# TC37XPD register map
Vendor: Infineon; Series: ATVMC; File version: 100
CPU: other r0p0, little endian, MPU, FPU, vendor SysTick, 4 interrupt priority bits
Registers are 32-bit, read-write, reset 0x0 unless marked. A register's access mark holds for its fields unless they carry their own. Offsets are from the block's base; [hi:lo] are bit positions; lines under a group give offsets from that group; {n}, {i} and the like mark numbered series; 'fields as' and 'values as' point back to an identical list.

## GTM (part 1 of 13)
Base 0xF0100000
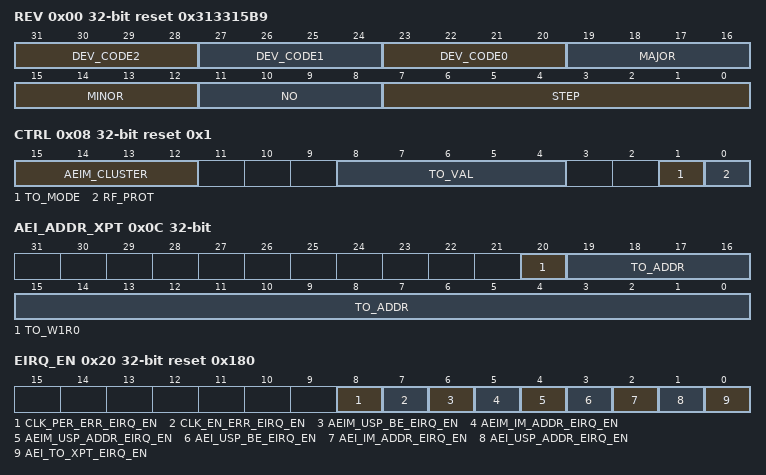
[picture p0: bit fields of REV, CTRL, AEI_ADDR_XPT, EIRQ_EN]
0x00 REV ro reset 0x313315B9 — GTM Version Control Register resetvalue={Application Reset:0x313315B9}
  [31:28] DEV_CODE2 — Device encoding digit 2. Device encoding digit 2.
  [27:24] DEV_CODE1 — Device encoding digit 1. Device encoding digit 1.
  [23:20] DEV_CODE0 — Device encoding digit 0. Device encoding digit 0.
  [19:16] MAJOR — Major version number. Define major version number of GTM specification.
  [15:12] MINOR — Minor version number. Define minor version number of GTM specification.
  [11:8] NO — Delivery number. Define delivery number of GTM specification.
  [7:0] STEP — Release step. GTM Release step
0x04 RST — GTM Global Reset Register resetvalue={Application Reset:0x0}
  [27] BRIDGE_MODE_WRDIS — GTM BRIDGE MODE write disable. This bit is write protected by bit RF PROT
0x08 CTRL access per field reset 0x1 — GTM Global Control Register resetvalue={Application Reset:0x1}
  [15:12] AEIM_CLUSTER ro — AEIM cluster number. These bits show the number of the AEI master port cluster which throws the interrupts AEIM USP ADDR AEIM IM ADDR and AEIM USP BE depending on the AEI master port access status.Note If one of the corresponding irq notify bits 6 4 is set this bit field will be frozen until the interrupt notify bits 6 4 are cleared.
  [8:4] TO_VAL rw — AEI timeout value. These bits define the number of cycles after which a timeout event occurs. When TO VAL equals zero 0 the AEI timeout functionality is disabled.
  [1] TO_MODE rw — AEI timeout mode
  [0] RF_PROT rw — RST and FORCINT protection
0x0C AEI_ADDR_XPT ro — GTM AEI Timeout Exception Address Register resetvalue={Application Reset:0x0}
  [20] TO_W1R0 — AEI timeout Read Write flag. This bit defines the AEI Read Write flag for which the AEI timeout event occurred.
  [19:0] TO_ADDR — AEI timeout address. This bit field defines the AEI address for which the AEI timeout event occurred.
0x10 IRQ group
  0x00 NOTIFY access per field — GTM Interrupt Notification Register resetvalue={Application Reset:0x0}
    [29] CLK_EN_EXP_STATE1 ro — Expected clock enable state. This bit field defines the GTM expected clk enable state for internal clock aei sys clk 2 at occurrence of the CLK EN ERR event. Function only available with INT CLK EN GEN 0b0 Read as zero in case of INT CLK EN GEN 0b1.
    [28] CLK_EN_EXP_STATE0 ro — Expected clock enable state. This bit field defines the GTM expected clk enable state for internal clock aei sys clk at occurrence of the CLK EN ERR event. Function only available with INT CLK EN GEN 0b0 Read as zero in case of INT CLK EN GEN 0b1.
    [25] CLK_EN_ERR_STATE1 ro — Erroneous clock enable state. This bit field defines the GTM external clk enable state for internal clock aei sys clk 2 at occurrence of the CLK EN ERR event. Function only available with INT CLK EN GEN 0b0 Read as zero in case of INT CLK EN GEN 0b1.
    [24] CLK_EN_ERR_STATE0 ro — Erroneous clock enable state. This bit field defines the GTM external clk enable state for internal clock aei sys clkat occurrence of the CLK EN ERR event. Function only available with INT CLK EN GEN 0b0 Read as zero in case of INT CLK EN GEN 0b1.
    [8] CLK_PER_ERR rw — Clock period error interrupt. This bit will be cleared on a CPU write access of value 1 . A read access leaves the bit unchanged. Read as zero in case of INT CLK EN GEN 0b1.
    [7] CLK_EN_ERR rw — Clock enable error interrupt. This bit will be cleared on a CPU write access of value 1 . A read access leaves the bit unchanged. Read as zero in case of INT CLK EN GEN 0b1.
    [6] AEIM_USP_BE rw — AEI master port unsupported byte enable interrupt. This bit will be cleared on a CPU write access of value 1 . A read access leaves the bit unchanged.
    [5] AEIM_IM_ADDR rw — AEI master port illegal Module address interrupt. This bit will be cleared on a CPU write access of value 1 . A read access leaves the bit unchanged.
    [4] AEIM_USP_ADDR rw — AEI master port unsupported address interrupt. This bit will be cleared on a CPU write access of value 1 . A read access leaves the bit unchanged.
    [3] AEI_USP_BE rw — AEI unsupported byte enable interrupt. This bit will be cleared on a CPU write access of value 1 . A read access leaves the bit unchanged.
    [2] AEI_IM_ADDR rw — AEI illegal Module address interrupt. This bit will be cleared on a CPU write access of value 1 . A read access leaves the bit unchanged.
    [1] AEI_USP_ADDR rw — AEI unsupported address interrupt. This bit will be cleared on a CPU write access of value 1 . A read access leaves the bit unchanged.
    [0] AEI_TO_XPT rw — AEI timeout exception occurred. This bit will be cleared on a CPU write access of value 1 . As the bit is rw otherwise no clear. A read access leaves the bit unchanged.
  0x04 EN — GTM Interrupt Enable Register resetvalue={Application Reset:0x0}
    [8] CLK_PER_ERR_IRQ_EN — CLK PER ERR IRQ interrupt enable. Read as zero in case of INT CLK EN GEN 0b1.
    [7] CLK_EN_ERR_IRQ_EN — CLK EN ERR IRQ interrupt enable. Read as zero in case of INT CLK EN GEN 0b1.
    [6] AEIM_USP_BE_IRQ_EN — AEIM USP BE IRQ interrupt enable
    [5] AEIM_IM_ADDR_IRQ_EN — AEIM IM ADDR IRQ interrupt enable
    [4] AEIM_USP_ADDR_IRQ_EN — AEI MUSP ADDR IRQ interrupt enable
    [3] AEI_USP_BE_IRQ_EN — AEI USP BE IRQ interrupt enable
    [2] AEI_IM_ADDR_IRQ_EN — AEI IM ADDR IRQ interrupt enable
    [1] AEI_USP_ADDR_IRQ_EN — AEI USP ADDR IRQ interrupt enable
    [0] AEI_TO_XPT_IRQ_EN — AEI TO XPT IRQ interrupt enable
  0x08 FORCINT — GTM Software Interrupt Generation Register resetvalue={Application Reset:0x0}
    [8] TRG_CLK_PER_ERR — Trigger CLK PER ERR IRQ interrupt by software. This bit is cleared automatically after write. This bit is write protected by bit RF PROT of CTRL Read as zero in case of INT CLK EN GEN 0b1.
    [7] TRG_CLK_EN_ERR — Trigger CLK EN ERR IRQ interrupt by software. This bit is cleared automatically after write. This bit is write protected by bit RF PROT of CTRL Read as zero in case of INT CLK EN GEN 0b1.
    [6] TRG_AEIM_USP_BE — Trigger AEIM USP BE IRQ interrupt by software. This bit is cleared automatically after write. This bit is write protected by bit RF PROT of CTRL
    [5] TRG_AEIM_IM_ADDR — Trigger AEIM IM ADDR IRQ interrupt by software. This bit is cleared automatically after write. This bit is write protected by bit RF PROT of CTRL
    [4] TRG_AEIM_USP_ADDR — Trigger AEIM USP ADDR IRQ interrupt by software. This bit is cleared automatically after write. This bit is write protected by bit RF PROT of CTRL
    [3] TRG_AEI_USP_BE — Trigger AEI USP BE IRQ interrupt by software. This bit is cleared automatically after write. This bit is write protected by bit RF PROT of CTRL
    [2] TRG_AEI_IM_ADDR — Trigger AEI IM ADDR IRQ interrupt by software. This bit is cleared automatically after write. This bit is write protected by bit RF PROT of CTRL
    [1] TRG_AEI_USP_ADDR — Trigger AEI USP ADDR IRQ interrupt by software. This bit is cleared automatically after write. This bit is write protected by bit RF PROT of CTRL
    [0] TRG_AEI_TO_XPT — Trigger AEI TO XPT IRQ interrupt by software. This bit is cleared automatically after write. This bit is write protected by bit RF PROT of CTRL
  0x0C MODE — GTM Top Level Interrupts Mode Selection Register resetvalue={Application Reset:0x0}
    [1:0] IRQ_MODE — Interrupt strategy mode selection for the AEI timeout and address monitoring interrupts. The interrupt modes are described in CROSSREFERENCE .Note This mode selection is only valid for the six interrupts described in section CROSSREFERENCE
0x20 EIRQ_EN reset 0x180 — GTM Error Interrupt Enable Register resetvalue={Application Reset:0x180}
  [8] CLK_PER_ERR_EIRQ_EN — CLK PER ERR EIRQ interrupt enable. Read as zero in case of INT CLK EN GEN 0b1. Read as zero shall be written as zero.
  [7] CLK_EN_ERR_EIRQ_EN — CLK EN ERR EIRQ interrupt enable. Read as zero in case of INT CLK EN GEN 0b1.
  [6] AEIM_USP_BE_EIRQ_EN — AEIM USP BE EIRQ error interrupt enable
  [5] AEIM_IM_ADDR_EIRQ_EN — AEIM IM ADDR EIRQ error interrupt enable
  [4] AEIM_USP_ADDR_EIRQ_EN — AEIM USP ADDR EIRQ error interrupt enable
  [3] AEI_USP_BE_EIRQ_EN — AEI USP BE EIRQ error interrupt enable
  [2] AEI_IM_ADDR_EIRQ_EN — AEI IM ADDR EIRQ error interrupt enable
  [1] AEI_USP_ADDR_EIRQ_EN — AEI USP ADDR EIRQ error interrupt enable
  [0] AEI_TO_XPT_EIRQ_EN — AEI TO XPT EIRQ error interrupt enable
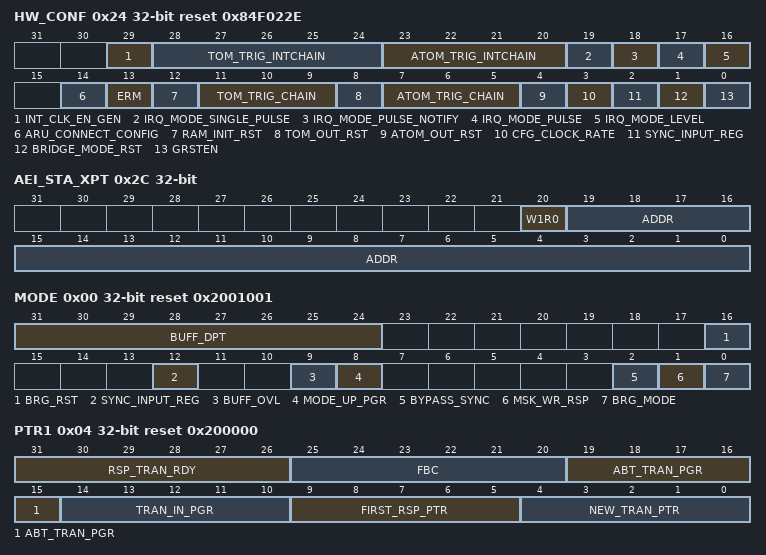
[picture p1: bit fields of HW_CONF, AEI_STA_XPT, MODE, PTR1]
0x24 HW_CONF ro reset 0x84F022E — GTM Hardware Configuration Register resetvalue={Application Reset:0x084F022E}
  [29] INT_CLK_EN_GEN — Internal clock enable generation
  [28:24] TOM_TRIG_INTCHAIN — TOM internal trigger chain length without synchronization register. It defines after which TOM channel count a synchronization register is introduced into trigger chain. Valid values are 1 to 16. 8 means that in channel 8 of the tom instances a synchronization register is placed.
  [23:20] ATOM_TRIG_INTCHAIN — ATOM internal trigger chain length without synchronization register. It defines after which ATOM channel count a synchronization register is introduced into trigger chain. Valid values are 1 to 8. 4 means that in channel 4 of the atom instances a synchronization register is placed.
  [19] IRQ_MODE_SINGLE_PULSE
  [18] IRQ_MODE_PULSE_NOTIFY
  [17] IRQ_MODE_PULSE
  [16] IRQ_MODE_LEVEL
  [14] ARU_CONNECT_CONFIG — Defines number of parallel ARU ports
  [13] ERM — Enable RAM1 MSB for available MCS modules. The bit reflects the state of the configuration parameter ERM mentioned in the specification of MCFG.
  [12] RAM_INIT_RST — RAM initialization from reset
  [11:9] TOM_TRIG_CHAIN — TOM trigger chain length without synchronization register. It defines after which TOM instance count a synchronization register is introduced into trigger chain after TOM TRIG lt i gt output if instance i and TOM TRIG lt i 1 gt input of instance i 1 . Valid values are 1 to 7. 1 means that after each instance a synchronization register is placed.
  [8] TOM_OUT_RST — TOM OUT reset level. This value represents the TOM output level after reset. The inverse value of this bit is the reset value of bit SL in all TOM channels.
  [7:5] ATOM_TRIG_CHAIN — ATOM trigger chain length without synchronization register. It defines after which ATOM instance count a synchronization register is introduced into trigger chain after ATOM TRIG lt i gt output if instance i and ATOM TRIG lt i 1 gt input of instance i 1 . Valid values are 1 to 7. 1 means that after each instance a synchronization register is placed.
  [4] ATOM_OUT_RST — ATOM OUT reset level. This value represents the ATOM output level after reset. The inverse value of this bit is the reset value of bit SL in all ATOM channels.
  [3] CFG_CLOCK_RATE — Clocks per ARU transfer. This value defines also the availability of configuration bits in register GTM CLS CLK CFG.if CFG CLOCK RATE 0 only the values 0b00 and 0b01 are valid for bit fields CLS x CLK DIV.if CFG CLOCK RATE 1 only the values 0b00 0b01 and 0b10 are valid for bit fields CLS x CLK DIV.
  [2] SYNC_INPUT_REG — Additional pipelined stage in synchronous bridge mode
  [1] BRIDGE_MODE_RST — Bridge mode after reset
  [0] GRSTEN — Global Reset Enable
0x28 CFG — GTM Configuration Register resetvalue={Application Reset:0x0}
  [0] SRC_IN_MUX — GTM TIM i AUX IN input source selection. See CROSSREFERENCE for details.
0x2C AEI_STA_XPT ro — GTM AEI Non Zero Status Register resetvalue={Application Reset:0x0}
  [20] W1R0 — AEI exception Read Write flag. This bit defines the AEI Read Write flag for which the AEI non zero event occurred. This bit field captures the address of the first AEI access resulting with a non zero AEI status signal. The bit field can be cleared by clearing the interrupt flags AEI USP ADDR AEI USP BE and AEI IM ADDR in the register GTM IRQ NOTIFY.
  [19:0] ADDR — AEI exception address. This bit field captures the address of the first AEI access resulting with a non zero AEI status signal. The bit field can be cleared by clearing the interrupt flags AEI USP ADDR AEI USP BE and AEI IM ADDR in the register GTM IRQ NOTIFY.
0x30 BRIDGE group
  0x00 MODE access per field reset 0x2001001 — GTM AEI Bridge Mode Register resetvalue={Application Reset:0x2001001}
    [31:24] BUFF_DPT ro — Buffer depth of AEI bridge. Signals the buffer depth of the GTM AEI bridge implementation. Reset value depends on the hardware configuration chosen by silicon vendor.
    [16] BRG_RST rw — Bridge software reset. This bit is cleared automatically after write.
    [12] SYNC_INPUT_REG ro — Additional pipelined stage in synchronous bridge mode. Reset value depends on the hardware configuration chosen by silicon vendor.
    [9] BUFF_OVL ro — Buffer overflow register. A buffer overflow can occur while multiple aborts are issued by the external bus or a pipelined instruction is started while FBC 0 see GTM BRIDGE PTR1 register .
    [8] MODE_UP_PGR ro — Mode update in progress
    [2] BYPASS_SYNC rw — Bypass synchronizer flipflops. Function only available with BRG MODE 1
    [1] MSK_WR_RSP rw — Mask write response. With active write buffer MSK WR RSP 1 execution of actions can be delayed due to previous inserted write actions in the transaction buffer which wait to be serviced. This can lead to the fact that an access on the bus to a different peripheral than the GTM might be executed earlier in time than the write access buffered in the GTM. Applications must be setup up with this in mind otherwise unexpected operation can happen.
    [0] BRG_MODE rw — Defines the operation mode for the AEI bridge. Reset value depends on the hardware configuration chosen by silicon vendor. BRG MODE shall not be written with 0.
  0x04 PTR1 ro reset 0x200000 — GTM AEI Bridge Pointer 1 Register resetvalue={Application Reset:0x200000}
    [31:26] RSP_TRAN_RDY — Response transactions ready. RSP TRAN RDY. Amount of ready response transactions.
    [25:20] FBC — Free buffer count. Number of free buffer entries. Initial value depends on the hardware configuration chosen by silicon vendor. see BUFF DPT in GTM BRIDGE MODE register .
    [19:15] ABT_TRAN_PGR — Aborted transaction in progress pointer. Aborted transaction in progress pointer.
    [14:10] TRAN_IN_PGR — Transaction in progress pointer acquire . Transaction in progress pointer.
    [9:5] FIRST_RSP_PTR — First response pointer. Signals the actual value of first response pointer.
    [4:0] NEW_TRAN_PTR — New transaction pointer. Signals the actual value of the new transaction pointer.
  0x08 PTR2 ro — GTM AEI Bridge Pointer 2 Register resetvalue={Application Reset:0x0}
    [4:0] TRAN_IN_PGR2 — Transaction in progress pointer aquire2 . Transaction in progress pointer 2.
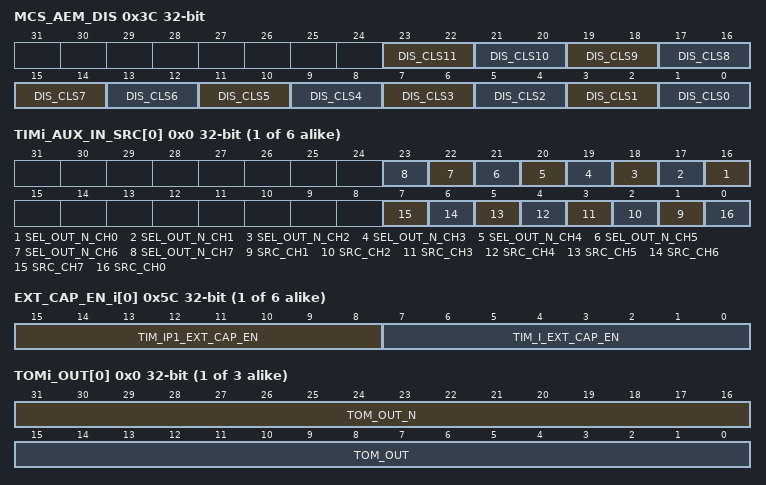
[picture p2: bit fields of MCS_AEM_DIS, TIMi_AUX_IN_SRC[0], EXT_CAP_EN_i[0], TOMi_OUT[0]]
0x3C MCS_AEM_DIS — GTM MCS Master Port Disable Register resetvalue={Application Reset:0x0}
  [2n+1:2n] DIS_CLS{n} (n=1..11) — Disable MCS AEIM access in cluster {n} see bit DIS CLS0
  [1:0] DIS_CLS0 — Disable MCS AEIM access in cluster 0. Multicore encoding in use DIS CLSx 1 defines the state of the signal Any read access to a DIS CLSx bit field will always result in a value 00 or 11 indicating current state. A modification of the state is only performed with the values 01 and 10. Writing the values 00 and 11 is always ignored.
0x40 AUX_IN_SRC group
  {0x0+4j} TIMi_AUX_IN_SRC[{j}] (j=0..5) — GTM TIM 0 Module AUX IN Source Selection Register resetvalue={Application Reset:0x0}
    [n+16] SEL_OUT_N_CH{n} (n=0..7) — Use DTM OUT or DTM OUT N signals as AUX IN source of TIM i channel {n}
    [n] SRC_CH{n} (n=1..7) — Defines AUX IN source of TIM i channel {n}. SEL OUT N CH{n} 0 SEL OUT N CH{n} 1
    [0] SRC_CH0 — Defines AUX IN source of TIM i channel 0. SEL OUT N CH0 SEL OUT N CH0 1
{0x5C+4i} EXT_CAP_EN_i[{i}] (i=0..5) — GTM External Capture Trigger Enable 0 resetvalue={Application Reset:0x0}
  [15:8] TIM_IP1_EXT_CAP_EN — TIM i 1 EXT CAPTURE signal forwarding enable
  [7:0] TIM_I_EXT_CAP_EN — TIM i EXT CAPTURE signal forwarding enable. The trigger event forwarding is possible from TIM i and TIM i 1 to MCS i .
0x80 OUT group
  {0x0+4j} TOMi_OUT[{j}] (j=0..2) ro — GTM TOM 0 Output Level resetvalue={Application Reset:0x0,Application Reset:0x0}
    [31:16] TOM_OUT_N — Output level snapshot of TOM i OUT N all channels. Actual level of primary output ports TOM i OUT N of channel 0 to 15 after DTM . Reset value depends on the hardware configuration chosen by silicon vendor. See GTM HW CONF for chosen value.
    [15:0] TOM_OUT — Output level snapshot of TOM i OUT all channels. Actual level of primary output ports TOM i OUT of channel 0 to 15 after DTM . Reset value depends on the hardware configuration chosen by silicon vendor. See GTM HW CONF for chosen value.
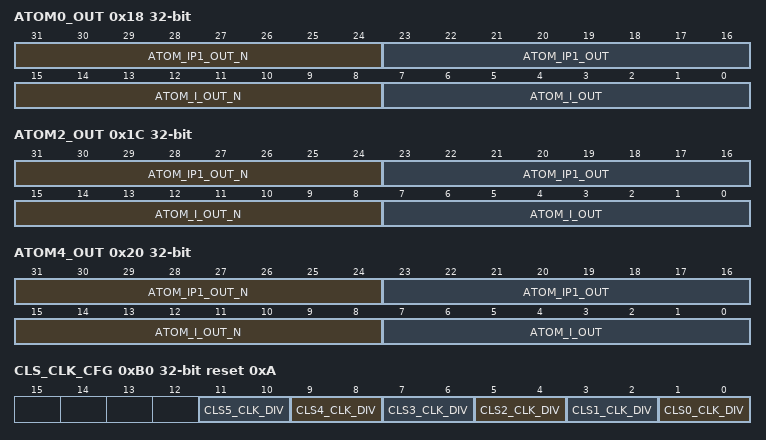
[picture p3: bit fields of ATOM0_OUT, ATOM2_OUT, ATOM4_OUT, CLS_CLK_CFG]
  0x18 ATOM0_OUT ro — GTM ATOM 0 Output Level resetvalue={Application Reset:0x0,Application Reset:0x0}
    [31:24] ATOM_IP1_OUT_N — Output level snapshot of ATOM k 1 OUT N all channels. Actual level of primary output ports ATOM k 1 OUT N of channel 0 to 7 after DTM
    [23:16] ATOM_IP1_OUT — Output level snapshot of ATOM k 1 OUT all channels. Actual level of primary output ports ATOM k 1 OUT of channel 0 to 7 after DTM
    [15:8] ATOM_I_OUT_N — Output level snapshot of ATOM k OUT N all channels. Actual level of primary output ports ATOM k OUT N of channel 0 to 7 after DTM
    [7:0] ATOM_I_OUT — Output level snapshot of ATOM k OUT all channels. Actual level of primary output ports ATOM k OUT of channel 0 to 7 after DTM .
  0x1C ATOM2_OUT ro — GTM ATOM 2 Output Level resetvalue={Application Reset:0x0,Application Reset:0x0}
    fields as OUT.ATOM0_OUT
  0x20 ATOM4_OUT ro — GTM ATOM 4 Output Level resetvalue={Application Reset:0x0,Application Reset:0x0}
    fields as OUT.ATOM0_OUT
0xB0 CLS_CLK_CFG reset 0xA (reset mask 0xFF55555F) — GTM Cluster Clock Configuration resetvalue={Application Reset:0x0AAAAAA,Application Reset:0x2AAAA,Application Reset:0x0AAA,Application Reset:0x0A,Application Reset:0x0AA}
  [2n+1:2n] CLS{n}_CLK_DIV (n=0..5) — Cluster 11 Clock Divider. This bit is only writable if bit field RF PROT of register GTM CTRL is cleared.
0x100 TBU group
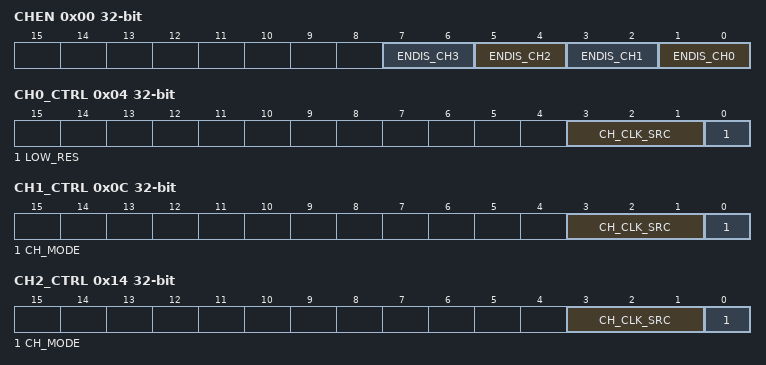
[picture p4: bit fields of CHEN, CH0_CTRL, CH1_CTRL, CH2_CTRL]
  0x00 CHEN — TBU Global Channel Enable resetvalue={Application Reset:0x0}
    [2n+1:2n] ENDIS_CH{n} (n=0..3) — TBU channel 3 enable disable control. Write Read
  0x04 CH0_CTRL — TBU Channel 0 Control Register resetvalue={Application Reset:0x0}
    [3:1] CH_CLK_SRC — Clock source for channel x x 0...2 time base counter. This value can only be modified if channel 0 is disabled.
    [0] LOW_RES — TBU CH0 BASE register resolution. The two resolutions for the TBU channel 0 can be used in the TIM channel 0 and the DPLL sub modules. This value can only be modified if channel 0 is disabled.
  0x08 CH0_BASE — TBU Channel 0 Base Register resetvalue={Application Reset:0x0}
    [26:0] BASE — Time base value for channel 0. The value of BASE can only be written if the TBU channel 0 is disabled. If channel 0 is enabled a read access to this register provides the current value of the underlying 27 bit counter.
  0x0C CH1_CTRL — TBU Channel 1 Control Register resetvalue={Application Reset:0x0}
    [3:1] CH_CLK_SRC — Clock source for channel 1 time base counter. This value can only be modified if channel 1 was disabled
    [0] CH_MODE — Channel mode. This value can only be modified if channel 1 is disabled. In Free running counter mode the CMU clock source specified by CH CLK SRC is used for the counter. In Forward Backward counter mode the SUB INC1c clock signal in combination with the DIR1 input signal is used to determine the counter direction and clock frequency.
  0x10 CH1_BASE — TBU Channel 1 Base Register resetvalue={Application Reset:0x0}
    [23:0] BASE — Time base value for channel y y 1 2 . The value of BASE can only be written if the corresponding TBU channel y is disabled. If the corresponding channel y is enabled a read access to this register provides the current value of the underlying counter.
  0x14 CH2_CTRL — TBU Channel 2 Control Register resetvalue={Application Reset:0x0}
    [3:1] CH_CLK_SRC — Clock source for channel 2 time base counter. This value can only be modified if channel 2 was disabled
    [0] CH_MODE — Channel mode. This value can only be modified if channel 2 is disabled. In Free running counter mode the CMU clock source specified by CH CLK SRC is used for the counter. In Forward Backward counter mode the SUB INC2c clock signal in combination with the DIR2 input signal is used to determine the counter direction and clock frequency.
  0x18 CH2_BASE — TBU Channel 2 Base Register resetvalue={Application Reset:0x0}
    fields as TBU.CH1_BASE
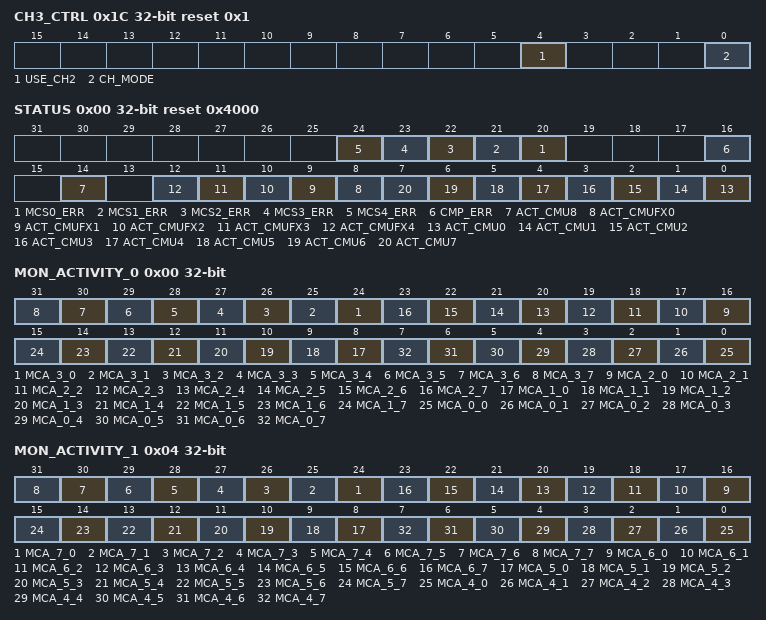
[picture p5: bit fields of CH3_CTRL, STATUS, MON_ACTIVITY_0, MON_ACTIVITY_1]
  0x1C CH3_CTRL access per field reset 0x1 — TBU Channel 3 Control Register resetvalue={Application Reset:0x1}
    [4] USE_CH2 rw — Channel selector for modulo counter. This value can only be modified if channel 3 was disabled
    [0] CH_MODE ro — Channel mode. 1 Forward backward counter mode
  0x20 CH3_BASE — TBU Channel 3 Base Register resetvalue={Application Reset:0x0}
    [23:0] BASE — Time base value for channel 3. The value of BASE can only be written if the corresponding TBU channel 3 is disabled. If the corresponding channel 3 is enabled a read access to this register provides the current value of the underlying counter.
  0x24 CH3_BASE_MARK — TBU Channel 3 Modulo Value Register resetvalue={Application Reset:0x0}
    [23:0] BASE_MARK — Modulo value for channel 3. The value of BASE MARK can only be written if the corresponding TBU channel 3 is disabled.
  0x28 CH3_BASE_CAPTURE ro — TBU Channel 3 Base Captured Register resetvalue={Application Reset:0x0}
    [23:0] BASE_CAPTURE — Captured value of time base channel 1 or 2. When USE CH2 0 TBU TS1 is captured and if USE CH2 is set TBU TS2 is captured.
0x180 MON group
  0x00 STATUS access per field reset 0x4000 — Monitor Status Register resetvalue={Application Reset:0x4000}
    [n+20] MCS{n}_ERR ro (n=0..4) — Error detected at MCS9. This bit will be readable only. Bits is set when the corresponding unit reports an error.
    [16] CMP_ERR ro — Error detected at CMP. This bit will be readable only. Bits is set when the corresponding unit reports an error.
    [14] ACT_CMU8 rw — CMU CLK8 activity. This bit will be cleared on a CPU write access of value 1. A read access leaves the bit unchanged. Bit is set when a rising edge is detected at the considered clock.
    [n+8] ACT_CMUFX{n} rw (n=0..4) — CMU CLKFX4 activity. This bit will be cleared on a CPU write access of value 1. A read access leaves the bit unchanged. Bits is set when a rising edge is detected at the considered clock.
    [n] ACT_CMU{n} rw (n=0..7) — CMU CLK7 activity. This bit will be cleared on a CPU write access of value 1. A read access leaves the bit unchanged. Bits is set when a rising edge is detected at the considered clock.
  0x04 ACTIVITY group
    0x00 MON_ACTIVITY_0 — Monitor Activity Register 0 resetvalue={Application Reset:0x0}
      [n+24] MCA_3_{n} (n=0..7) — Activity of check performed in module MCS 3 at channel 7. This bit will be cleared on a CPU write access of value 1. A read access leaves the bit unchanged.
      [n+16] MCA_2_{n} (n=0..7) — Activity of check performed in module MCS 2 at channel 7. This bit will be cleared on a CPU write access of value 1. A read access leaves the bit unchanged.
      [n+8] MCA_1_{n} (n=0..7) — Activity of check performed in module MCS 1 at channel 7. This bit will be cleared on a CPU write access of value 1. A read access leaves the bit unchanged.
      [n] MCA_0_{n} (n=0..7) — Activity of check performed in module MCS 0 at channel 7. This bit will be cleared on a CPU write access of value 1. A read access leaves the bit unchanged.
    0x04 MON_ACTIVITY_1 — Monitor Activity Register 1 resetvalue={Application Reset:0x0}
      [n+24] MCA_7_{n} (n=0..7) — Activity of check performed in module MCS 7 at channel 7 MCA 7 7. This bit will be cleared on a CPU write access of value 1. A read access leaves the bit unchanged.
      [n+16] MCA_6_{n} (n=0..7) — Activity of check performed in module MCS 6 at channel 7. This bit will be cleared on a CPU write access of value 1. A read access leaves the bit unchanged.
      [n+8] MCA_5_{n} (n=0..7) — Activity of check performed in module MCS 5 at channel 7. This bit will be cleared on a CPU write access of value 1. A read access leaves the bit unchanged.
      [n] MCA_4_{n} (n=0..7) — Activity of check performed in module MCS 4 at channel 7. This bit will be cleared on a CPU write access of value 1. A read access leaves the bit unchanged.
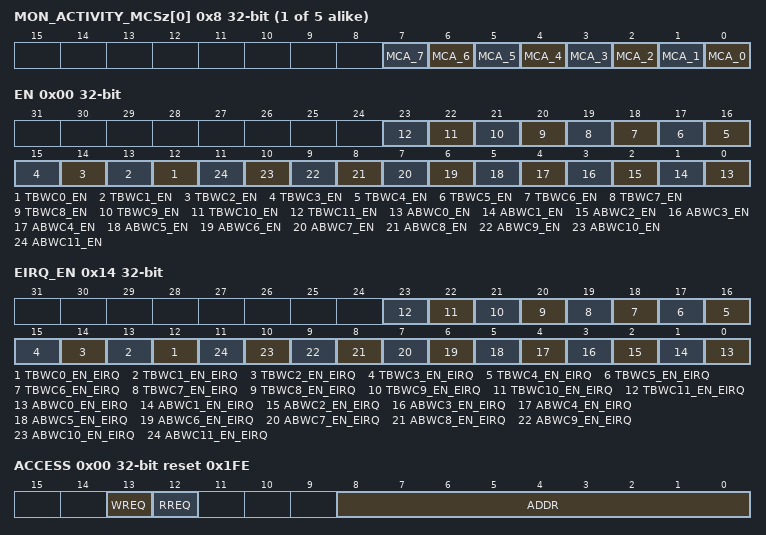
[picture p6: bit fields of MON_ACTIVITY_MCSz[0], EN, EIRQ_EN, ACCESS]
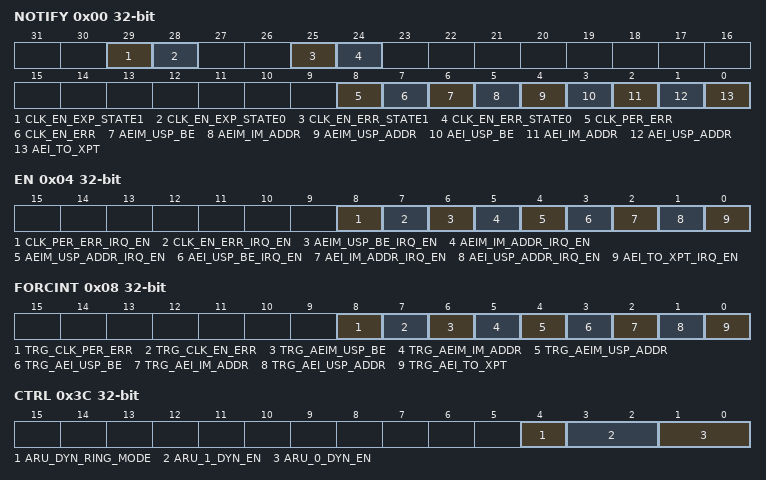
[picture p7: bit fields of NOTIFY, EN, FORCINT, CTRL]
    {0x8+4k} MON_ACTIVITY_MCSz[{k}] (k=0..4) — Monitor Activity Register for MCS 0 resetvalue={Application Reset:0x0}
      [n] MCA_{n} (n=0..7) — Activity of check performed in module MCS z at channel 7. This bit will be cleared on a CPU write access of value 1. A read access leaves the bit unchanged.
0x200 CMP group
  0x00 EN — CMP Comparator Enable Register resetvalue={Application Reset:0x0}
    [n+12] TBWC{n}_EN (n=0..11) — Enable comparator 11 in TBWC. see CROSSREFERENCE
    [n] ABWC{n}_EN (n=0..11) — Enable comparator 11 in ABWC. see CROSSREFERENCE
  0x04 IRQ group
    0x00 NOTIFY — CMP Event Notification Register resetvalue={Application Reset:0x0}
      [n+12] TBWC{n} (n=0..11) — TOM sub modules outputs bitwise comparator 11 error indication. This bit will be cleared on a CPU write access of value 1 . A read access leaves the bit unchanged.
      [n] ABWC{n} (n=0..11) — Error indication for ABWC11. This bit will be cleared on a CPU write access of value 1 . As the bit is rw otherwise no clear. A read access leaves the bit unchanged.
    0x04 EN — CMP Interrupt Enable Register resetvalue={Application Reset:0x0}
      [n+12] TBWC{n}_EN_IRQ (n=0..11) — Enable TBWC11 interrupt source for CMP IRQ line
      [n] ABWC{n}_EN_IRQ (n=0..11) — Enable ABWC11 interrupt source for CMP IRQ line
    0x08 FORCINT — CMP Interrupt Force Register resetvalue={Application Reset:0x0}
      [n+12] TRG_TBWC{n} (n=0..11) — Trigger TBWCx bit in CMP IRQ NOTIFY register by software. This bit is cleared automatically after write.
      [n] TRG_ABWC{n} (n=0..11) — Trigger ABWC11 bit in CMP IRQ NOTIFY register by software. This bit is cleared automatically after write. This bit is write protected by bit RF PROT of register GTM CTRL.
    0x0C MODE — CMP Interrupt Mode Configuration Register resetvalue={Application Reset:0x0}
      [1:0] IRQ_MODE — IRQ mode selection IRQ MODE. The interrupt modes are described in CROSSREFERENCE
  0x14 EIRQ_EN — CMP error interrupt enable register resetvalue={Application Reset:0x0}
    [n+12] TBWC{n}_EN_EIRQ (n=0..11) — Enable TBWC11 interrupt source for CMP EIRQ line
    [n] ABWC{n}_EN_EIRQ (n=0..11) — Enable ABWC11 interrupt source for CMP EIRQ line
0x280 ARU group
  0x00 ACCESS reset 0x1FE — ARU Access Register resetvalue={Application Reset:0x1FE}
    [13] WREQ — Initiate write request. This bit is cleared automatically after transaction. Moreover it can be cleared by software to cancel a write request. WREQ bit is only writable if RREQ bit is zero so to switch from WREQ to RREQ a cancel request has to be performed before. Configuring both RREQ and WREQ bits results in a read request so WREQ bit will not be set The data is provided at address ADDR. This address has to be programmed as the source address in the destination sub module channel. In worst case the data is provided after one full ARU round trip.
    [12] RREQ — Initiate read request. This bit is cleared automatically after transaction. Moreover it can be cleared by software to cancel a read request. RREQ bit is only writable if WREQ bit is zero so to switch from RREQ to WREQ a cancel request has to be performed before. Configuring both RREQ and WREQ bits results in a read request so RREQ bit will be set if the WREQ bit of the register isn t already set. The ARU read request on address ADDR is served immediately when no other destination has actually a read request when the RREQ bit is set by CPU. In a worst case scenario the read request is served after one round trip of the ARU but this is only the case when every destination channel issues a read request at consecutive points in time.
    [8:0] ADDR — ARU address. Define the ARU address used for transferring data. For an ARU write request the preferred address 0x0 have to be used. A write request to the address 0x1FF always full address or 0x1FE always empty address are ignored and doesn t have any effect. ARU address bits ADDR are only writable if RREQ and WREQ bits are zero.
  0x04 DATA_H — ARU Access Register Upper Data Word resetvalue={Application Reset:0x0}
    [28:0] DATA — Upper ARU data word. Transfer upper ARU data word addressed by ADDR. The data bits 24 to 52 of an ARU word are mapped to the data bits 0 to 28 of this register.
  0x08 DATA_L — ARU Access Register Lower Data Word resetvalue={Application Reset:0x0}
    [28:0] DATA — Lower ARU data word. Transfer lower ARU data word addressed by ADDR. The data bits 0 to 23 of an ARU word are mapped to the data bits 0 to 23 of this register and the data bits 48 to 52 of an ARU word are mapped to the data bits 24 to 28 of this register when data is read by the CPU. For writing data into the ARU by the CPU the bits 24 to 28 are not transferred to bit 48 to 52 of the ARU word. Only bits 0 to 23 are written to bits 0 to 23 of the ARU word.
  0x0C DBG group
    0x00 ACCESS0 reset 0x1FE — ARU Debug Access Channel 0 resetvalue={Application Reset:0x1FE}
      [8:0] ADDR — ARU debugging address. Define address of ARU debugging channel 0.
    0x04 DATA0_H ro — ARU Debug Access 0 Transfer Register Upper Data Word resetvalue={Application Reset:0x0}
      [28:0] DATA — Upper debug data word. Transfer upper ARU data word addressed by register DBG ACCESS0 . The data bits 24 to 52 of an ARU word are mapped to the data bits 0 to 28 of this register The interrupt ARU NEW DATA0 IRQ is raised if a new data word is available.
    0x08 DATA0_L ro — ARU Debug Access 0 Transfer Register Lower Data Word resetvalue={Application Reset:0x0}
      [28:0] DATA — Lower debug data word. Transfer lower ARU data word addressed by register DBG ACCESS0 . The data bits 0 to 23 of an ARU word are mapped to the data bits 0 to 23 of this register and the data bits 48 to 52 of an ARU word is mapped to the data bits 24 to 28 of this register. The interrupt ARU NEW DATA0 IRQ is raised if a new data word is available.
    0x0C ACCESS1 reset 0x1FE — ARU Debug Access Channel 1 resetvalue={Application Reset:0x1FE}
      [8:0] ADDR — ARU debugging address. Define address of ARU debugging channel 1.
    0x10 DATA1_H ro — ARU Debug Access 1 Transfer Register Upper Data Word resetvalue={Application Reset:0x0}
      [28:0] DATA — Upper debug data word. Transfer upper ARU data word addressed by register DBG ACCESS1 . The data bits 24 to 52 of an ARU word are mapped to the data bits 0 to 28 of this register. The interrupt ARU NEW DATA1 IRQ is raised if a new data word is available.
    0x14 DATA1_L ro — ARU Debug Access 1 Transfer Register Lower Data Word resetvalue={Application Reset:0x0}
      [28:0] DATA — Lower debug data word DATA. Transfer lower ARU data word addressed by register DBG ACCESS1 . The data bits 0 to 23 of an ARU word are mapped to the data bits 0 to 23 of this register and the data bits 48 to 52 of an ARU word is mapped to the data bits 24 to 28 of this register. The interrupt ARU NEW DATA1 IRQ is raised if a new data word is available.
  0x24 IRQ group
    0x00 NOTIFY — ARU Interrupt Notification Register resetvalue={Application Reset:0x0}
      [2] ACC_ACK — AEI to ARU access finished on read access data are valid. This bit will be cleared on a CPU write access of value 1 . As the bit is rw otherwise no clear. A read access leaves the bit unchanged.
      [1] NEW_DATA1 — Data was transferred for addr ARU DBG ACCESS1. This bit will be cleared on a CPU write access of value 1 . As the bit is rw otherwise no clear. A read access leaves the bit unchanged.
      [0] NEW_DATA0 — Data was transferred for addr ARU DBG ACCESS0. This bit will be cleared on a CPU write access of value 1 . As the bit is rw otherwise no clear. A read access leaves the bit unchanged.
    0x04 EN — ARU Interrupt Enable Register resetvalue={Application Reset:0x0}
      [2] ACC_ACK_IRQ_EN — ACC ACK IRQ interrupt enable
      [1] NEW_DATA1_IRQ_EN — ARU NEW DATA1 IRQ interrupt enable
      [0] NEW_DATA0_IRQ_EN — ARU NEW DATA0 IRQ interrupt enable
    0x08 FORCINT — ARU Force Interrupt Register resetvalue={Application Reset:0x0}
      [2] TRG_ACC_ACK — Trigger ACC ACK interrupt. Note This bit is cleared automatically after write. This bit is write protected by bit RF PROT of register GTM CTRL.
      [1] TRG_NEW_DATA1 — Trigger new data 1 interrupt. Note This bit is cleared automatically after write. This bit is write protected by bit RF PROT of register GTM CTRL.
      [0] TRG_NEW_DATA0 — Trigger new data 0 interrupt. Note This bit is cleared automatically after write. This bit is write protected by bit RF PROT of register GTM CTRL.
    0x0C MODE — ARU Interrupt Mode Register resetvalue={Application Reset:0x0}
      [1:0] IRQ_MODE — IRQ mode selection. The interrupt modes are described in CROSSREFERENCE .
  0x34 CADDR_END reset 0x60 — ARU caddr Counter End Value Register resetvalue={Application Reset:0x60}
    [6:0] CADDR_END — Set end value of ARU caddr counter. The ARU roundtrip counter aru caddr runs from zero to caddr end value. Shorten the ARU roundtrip cycle by setting a smaller number than the defined reset value will cause that not all ARU connected modules will be served. Making the roundtrip cycle longer than the reset value would cause longer ARU roundtrip time and as a result some ARU connected modules will not be served as fast as possible for this device. This bit is write protected by bit RF PROT of register GTM CTRL
  0x3C CTRL — ARU Enable Dynamic Routing Register resetvalue={Application Reset:0x0}
    [4] ARU_DYN_RING_MODE — Enable dynamic routing ring mode. Dynamic routing ring mode for both ARU 0 and ARU 1.
    [3:2] ARU_1_DYN_EN — Enable dynamic routing for ARU 1. Dynamic routing enable of ARU 1. Write of following double bit values is possible If dynamic routing is disabled the normal ARU routing scheme for ARU 1 is executed.
    [1:0] ARU_0_DYN_EN — Enable dynamic routing for ARU 0. Dynamic routing enable of ARU 0. Write of following double bit values is possible If dynamic routing is disabled the normal ARU routing scheme for ARU 0 is executed.
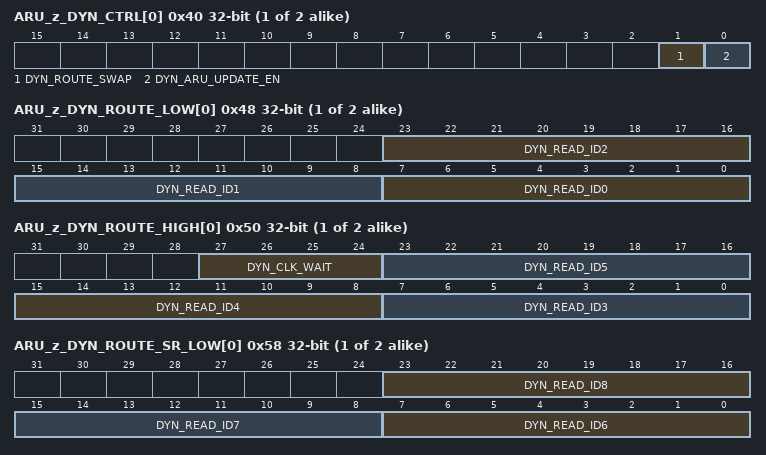
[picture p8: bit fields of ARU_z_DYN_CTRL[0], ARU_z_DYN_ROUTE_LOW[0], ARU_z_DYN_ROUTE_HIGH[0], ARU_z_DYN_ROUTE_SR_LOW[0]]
  {0x40+4j} ARU_z_DYN_CTRL[{j}] (j=0..1) — ARU 0 Dynamic Routing Control Register resetvalue={Application Reset:0x0}
    [1] DYN_ROUTE_SWAP — Enable swapping DYN ROUTE SR with DYN ROUTE register. Enable swapping DYN ROUTE SR with DYN ROUTE register.
    [0] DYN_ARU_UPDATE_EN — Enable reload of DYN ROUTE register from ARU itself. Enable reload of DYN ROUTE register from ARU itself.
  {0x48+4j} ARU_z_DYN_ROUTE_LOW[{j}] (j=0..1) — ARU 0 Lower Bits of DYN ROUTE Register resetvalue={Application Reset:0x0}
    [23:16] DYN_READ_ID2 — ARU read ID 2. ARU read ID 2 for dynamic routing.
    [15:8] DYN_READ_ID1 — ARU read ID 2. ARU read ID 1 for dynamic routing.
    [7:0] DYN_READ_ID0 — ARU read ID 0. ARU read ID 0 for dynamic routing.
  {0x50+4j} ARU_z_DYN_ROUTE_HIGH[{j}] (j=0..1) — ARU 0 Higher Bits of DYN ROUTE Register resetvalue={Application Reset:0x0}
    [27:24] DYN_CLK_WAIT — Number of clk cycles for dynamic routing. Defines the number of clk cycles between each dynamic routing ID.
    [23:16] DYN_READ_ID5 — ARU read ID 5. ARU read ID 5 for dynamic routing.
    [15:8] DYN_READ_ID4 — ARU read ID 4. ARU read ID 4 for dynamic routing.
    [7:0] DYN_READ_ID3 — ARU read ID 3. ARU read ID 3 for dynamic routing.
  {0x58+4j} ARU_z_DYN_ROUTE_SR_LOW[{j}] (j=0..1) — ARU 0 Shadow Register for ARU 0 DYN ROUTE LOW resetvalue={Application Reset:0x0}
    [23:16] DYN_READ_ID8 — ARU read ID 8. ARU read ID 8 for dynamic routing. These bits are mapped to ARU data bits aru data 23 16 .
    [15:8] DYN_READ_ID7 — ARU read ID 7. ARU read ID 7 for dynamic routing. These bits are mapped to ARU data bits aru data 15 8 .
    [7:0] DYN_READ_ID6 — ARU read ID 6. ARU read ID 6 for dynamic routing. These bits are mapped to ARU data bits aru data 7 0 .
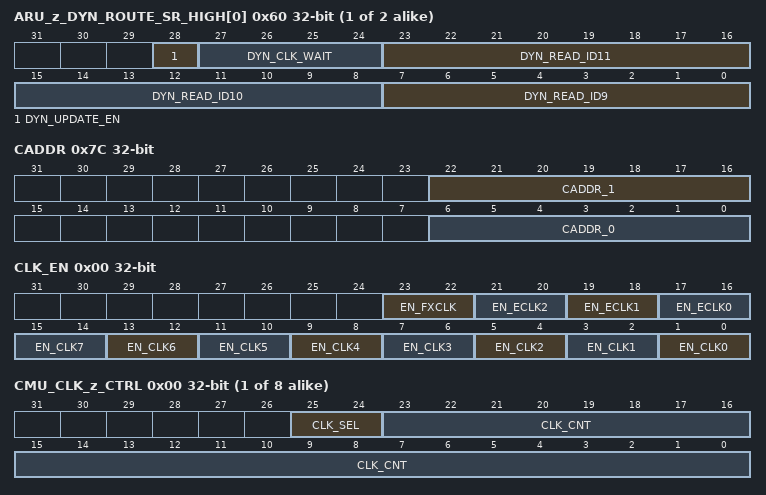
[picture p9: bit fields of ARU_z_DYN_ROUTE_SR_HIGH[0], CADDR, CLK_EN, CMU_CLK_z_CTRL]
  {0x60+4j} ARU_z_DYN_ROUTE_SR_HIGH[{j}] (j=0..1) — ARU 0 Shadow Register for ARU 0 DYN ROUTE HIGH resetvalue={Application Reset:0x0}
    [28] DYN_UPDATE_EN — Update enable from shadow register. Enable update ARU z DYN ROUTE LOW HIGH registers from shadow registers ARU z DYN ROUTE SR LOW HIGH . This bit is mapped to ARU data bit aru data 52 .
    [27:24] DYN_CLK_WAIT — Number of clk cycles for dynamic routing. Defines the number of clk cycles between each dynamic routing ID. These bits are mapped to ARU data bits aru data 51 48 .
    [23:16] DYN_READ_ID11 — ARU read ID 11. ARU read ID 11 for dynamic routing. These bits are mapped to ARU data bits aru data 47 40 .
    [15:8] DYN_READ_ID10 — ARU read ID 10. ARU read ID 10 for dynamic routing. These bits are mapped to ARU data bits aru data 39 32 .
    [7:0] DYN_READ_ID9 — ARU read ID 9. ARU read ID 9 for dynamic routing. These bits are mapped to ARU data bits aru data 31 24 .
  {0x68+4j} ARU_z_DYN_RDADDR[{j}] (j=0..1) — ARU 0 Read ID for Dynamic Routing resetvalue={Application Reset:0x0}
    [8:0] DYN_ARU_RDADDR — ARU read address ID to reload the DYN ROUTE register. ARU read address ID to reload the DYN ROUTE register from ARU itself.
  0x7C CADDR ro — ARU caddr Counter Value resetvalue={Application Reset:0x0}
    [22:16] CADDR_1 — Value of ARU 1 caddr counter
    [6:0] CADDR_0 — Value of ARU 0 caddr counter
0x300 CMU group
  0x00 CLK_EN — CMU Clock Enable Register resetvalue={Application Reset:0x0}
    [23:22] EN_FXCLK — Enable all CMU FXCLK see bits 1 0. An enable to EN FXCLK from disable state will be reset internal fixed clock counters.
    [21:20] EN_ECLK2 — Enable ECLK 2 generation sub unit. Coding see bit EN CLKx.
    [19:18] EN_ECLK1 — Enable ECLK 2 generation sub unit. Coding see bit EN CLKx.
    [17:16] EN_ECLK0 — Enable ECLK 2 generation sub unit. Coding see bit EN CLKx.
    [2n+1:2n] EN_CLK{n} (n=0..7) — Enable clock source x. Any read access to an EN CLK x EN ECLK z or EN FXCLK bit field will always result in a value 00 or 11 indicating current state. A modification of the state is only performed with the values 01 and 10. Writing the values 00 and 11 is always ignored. Any disabling to EN CLK x will be reset internal counters for configurable clocks.
  0x04 GCLK_NUM reset 0x1 — CMU Global Clock Control Numerator resetvalue={Application Reset:0x1}
    [23:0] GCLK_NUM — GCLK NUM. Value can only be modified when all clock enables EN CLK x and the EN FXCLK are disabled. The CMU hardware alters the content of CMU GCLK NUM and CMU GCLK DEN automatically to 0x1 if CMU GCLK NUM is specified less than CMU GCLK DEN or one of the values is specified with a value zero. Thus a secure way for altering the values is writing twice to the register CMU GCLK NUM followed by a single write to register CMU GCLK DEN .
  0x08 GCLK_DEN reset 0x1 — CMU Global Clock Control Denominator resetvalue={Application Reset:0x1}
    [23:0] GCLK_DEN — GCLK DEN. Value can only be modified when all clock enables EN CLK x and the EN FXCLK are disabled. The CMU hardware alters the content of CMU GCLK NUM and CMU GCLK DEN automatically to 0x1 if CMU GCLK NUM is specified less than CMU GCLK DEN or one of the values is specified with a value zero. Thus a secure way for altering the values is writing twice to the register CMU GCLK NUM followed by a single write to register CMU GCLK DEN .
  {0xC+4j} CLK[{j}] (j=0..7) group
    0x00 CMU_CLK_z_CTRL — CMU Control for Clock Source 0 resetvalue={Application Reset:0x0}
      [25:24] CLK_SEL — Clock source selection for CMU CLKz. Value can only be modified when clock enable EN CLKz and EN ECLK1 are disabled. Note The existence and interpretation of this bit field depends on z. z gt 5
      [23:0] CLK_CNT — Clock count. Defines count value for the clock divider. Value can only be modified when clock enable EN CLKz and EN ECLK1 are disabled.
  {0x2C+8j} ECLK[{j}] (j=0..2) group
    0x00 CMU_ECLK_z_NUM reset 0x1 — CMU External Clock 0 Control Numerator resetvalue={Application Reset:0x1}
      [23:0] ECLK_NUM — ECLK NUM. Numerator for external clock divider. Defines numerator of the fractional divider. Value can only be modified when clock enable EN ECLK z disabled. The CMU hardware alters the content of CMU ECLK z NUM and CMU ECLK z DEN automatically to 0x1 if CMU ECLK z NUM is specified less than CMU ECLK z DEN or one of the values is specified with a value zero. Thus a secure way for altering the values is writing twice to the register CMU ECLK z NUM followed by a single write to register CMU ECLK z DEN .
    0x04 CMU_ECLK_z_DEN reset 0x1 — CMU External Clock 0 Control Denominator resetvalue={Application Reset:0x1}
      [23:0] ECLK_DEN — ECLK DEN. Denominator for external clock divider. Defines denominator of the fractional divider Value can only be modified when clock enable EN ECLK z disabled. The CMU hardware alters the content of CMU ECLK z NUM and CMU ECLK z DEN automatically to 0x1 if CMU ECLK z NUM is specified less than CMU ECLK z DEN or one of the values is specified with a value zero. Thus a secure way for altering the values is writing twice to the register CMU ECLK z NUM followed by a single write to register CMU ECLK z DEN .
  0x48 GLB_CTRL — CMU Synchronizing ARU and Clock Source resetvalue={Application Reset:0x0}
    [0] ARU_ADDR_RSTGLB — Reset ARU caddr counter and ARU dynamic route counter. Writing value 1 to this bit field results in a request to reset the ARU caddr counter and ARU dynamic route counter. The next following write access to register CMU CLK EN applies the ARU caddr counter reset ARU dynamic route counter reset and resets this bit. This feature can be used to synchronize the ARU round trip time to the CMU clocks. This bit is write protected. Before writing to this bit set bit RF PROT of register GTM CTRL to 0.
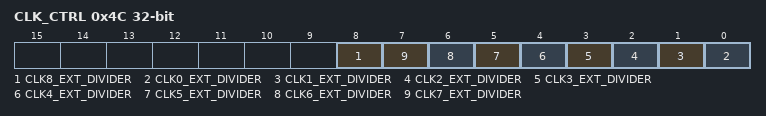
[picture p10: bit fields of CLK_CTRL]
  0x4C CLK_CTRL — CMU Control for Clock Source Selection resetvalue={Application Reset:0x0}
    [8] CLK8_EXT_DIVIDER — Clock source selection for CMU CLK8. Value can only be modified when EN ECLK0 is disabled.
    [n] CLK{n}_EXT_DIVIDER (n=0..7) — Clock source selection for CMU CLK {n} CTRL. Value can only be modified when clock enable EN CLK{n} and EN ECLK1 are disabled.
